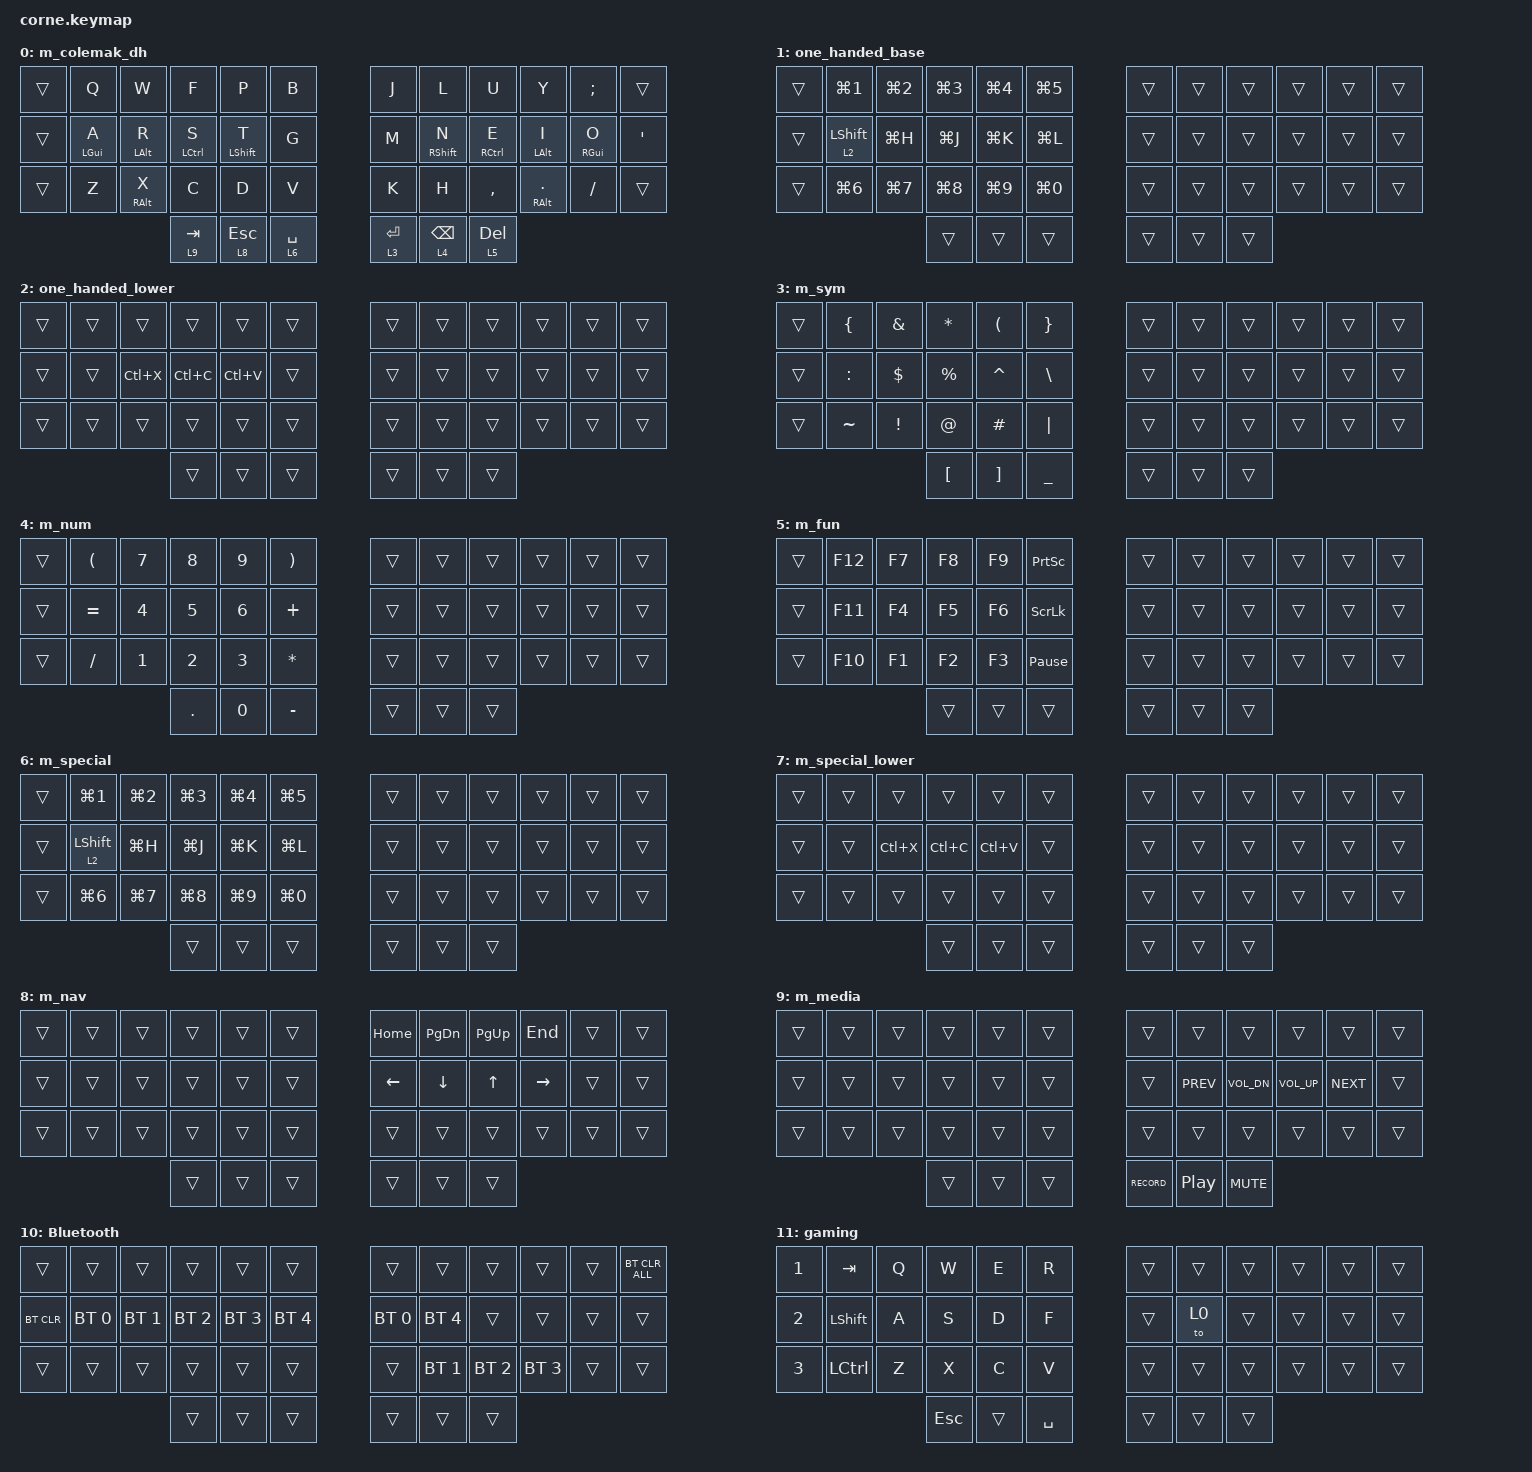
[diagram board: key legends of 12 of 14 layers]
/*
 * Copyright (c) 2020 The ZMK Contributors
 *
 * SPDX-License-Identifier: MIT
 */

#include <behaviors.dtsi>
#include <dt-bindings/zmk/bt.h>
#include <dt-bindings/zmk/keys.h>

/ {
    behaviors {
        lh_pht: left_hand_positional_hold_tap {
            compatible = "zmk,behavior-hold-tap";
            label = "LEFT_POSITIONAL_HOLD_TAP";
            bindings = <&kp>, <&kp>;

            #binding-cells = <2>;
            flavor = "tap-unless-interrupted";
            tapping-term-ms = <500>;
            hold-trigger-key-positions = <30 18 6 7 31 19 20 8 32 33 21 9 10 22 34 35 23 11>;
            quick-tap-ms = <200>;
            hold-trigger-on-release;
        };

        rh_pht: right_hand_positional_hold_tap {
            compatible = "zmk,behavior-hold-tap";
            label = "RIGHT_HAND_POSITIONAL_HOLD_TAP";
            bindings = <&kp>, <&kp>;

            #binding-cells = <2>;
            flavor = "tap-unless-interrupted";
            tapping-term-ms = <500>;
            quick-tap-ms = <200>;
            hold-trigger-key-positions = <0 1 2 3 4 5 12 13 14 15 16 17 24 25 26 27 28 29>;
            hold-trigger-on-release;
        };

        hl_ts: hold_layer_tap_sticky {
            compatible = "zmk,behavior-hold-tap";
            label = "HOLD_LAYER_TAP_STICKY";
            bindings = <&mo>, <&sk>;

            #binding-cells = <2>;
            tapping-term-ms = <100>;
        };

        lh_bpht: lh_bpht {
            compatible = "zmk,behavior-hold-tap";
            label = "LH_BPHT";
            bindings = <&kp>, <&kp>;

            #binding-cells = <2>;
            flavor = "balanced";
            tapping-term-ms = <500>;
            hold-trigger-key-positions = <30 18 6 7 31 19 20 8 32 33 21 9 10 22 34 35 23 11>;
            hold-trigger-on-release;
            quick-tap-ms = <200>;
        };

        rh_bpht: rh_bpht {
            compatible = "zmk,behavior-hold-tap";
            label = "RH_BPHT";
            bindings = <&kp>, <&kp>;

            #binding-cells = <2>;
            flavor = "balanced";
            tapping-term-ms = <500>;
            hold-trigger-on-release;
            hold-trigger-key-positions = <12 13 14 15 16 24 25 26 27 28 0 1 2 3 4 5 12 13 14 15 16 17 24 25 26 27 28 29>;
            quick-tap-ms = <200>;
        };

        balanced: balanced {
            compatible = "zmk,behavior-hold-tap";
            label = "BALANCED";
            bindings = <&kp>, <&kp>;

            #binding-cells = <2>;
            flavor = "balanced";
            tapping-term-ms = <1000>;
            quick-tap-ms = <200>;
        };

        lt_qt: lt_qt {
            compatible = "zmk,behavior-hold-tap";
            label = "LT_QT";
            bindings = <&mo>, <&kp>;

            #binding-cells = <2>;
            tapping-term-ms = <200>;
            quick-tap-ms = <200>;
            flavor = "tap-preferred";
        };
    };

    combos {
        compatible = "zmk,combos";

        one_handed {
            bindings = <&tog 1>;
            key-positions = <14 13 15 16>;
            layers = <13 1 2>;
        };
    };

    keymap {
        compatible = "zmk,keymap";

        m_colemak_dh {
            bindings = <
&trans  &kp Q                 &kp W                 &kp F              &kp P               &kp B             &kp J         &kp L               &kp U              &kp Y                 &kp SEMI          &trans
&trans  &balanced LEFT_GUI A  &balanced LEFT_ALT R  &balanced LCTRL S  &balanced LSHIFT T  &kp G             &kp M         &balanced RSHFT N   &balanced RCTRL E  &balanced LEFT_ALT I  &balanced RGUI O  &kp SQT
&trans  &kp Z                 &balanced RALT X      &kp C              &kp D               &kp V             &kp K         &kp H               &kp COMMA          &balanced RALT DOT    &kp FSLH          &trans
                                                    &lt_qt 9 TAB       &lt_qt 8 ESC        &lt_qt 6 SPACE    &lt_qt 3 RET  &lt_qt 4 BACKSPACE  &lt_qt 5 DEL
            >;
        };

        one_handed_base {
            bindings = <
&trans  &kp LG(N1)       &kp LG(N2)  &kp LG(N3)  &kp LG(N4)  &kp LG(N5)    &trans  &trans  &trans  &trans  &trans  &trans
&trans  &hl_ts 2 LSHIFT  &kp LG(H)   &kp LG(J)   &kp LG(K)   &kp LG(L)     &trans  &trans  &trans  &trans  &trans  &trans
&trans  &kp LG(N6)       &kp LG(N7)  &kp LG(N8)  &kp LG(N9)  &kp LG(N0)    &trans  &trans  &trans  &trans  &trans  &trans
                                     &trans      &trans      &trans        &trans  &trans  &trans
            >;
        };

        one_handed_lower {
            bindings = <
&trans  &trans  &trans     &trans     &trans     &trans    &trans  &trans  &trans  &trans  &trans  &trans
&trans  &trans  &kp LC(X)  &kp LC(C)  &kp LC(V)  &trans    &trans  &trans  &trans  &trans  &trans  &trans
&trans  &trans  &trans     &trans     &trans     &trans    &trans  &trans  &trans  &trans  &trans  &trans
                           &trans     &trans     &trans    &trans  &trans  &trans
            >;
        };

        m_sym {
            bindings = <
&trans  &kp LBRC   &kp AMPS         &kp ASTERISK      &kp LEFT_PARENTHESIS  &kp RIGHT_BRACE    &trans  &trans  &trans  &trans  &trans  &trans
&trans  &kp COLON  &kp DLLR         &kp PERCENT       &kp CARET             &kp BACKSLASH      &trans  &trans  &trans  &trans  &trans  &trans
&trans  &kp TILDE  &kp EXCLAMATION  &kp AT            &kp HASH              &kp PIPE           &trans  &trans  &trans  &trans  &trans  &trans
                                    &kp LEFT_BRACKET  &kp RIGHT_BRACKET     &kp UNDERSCORE     &trans  &trans  &trans
            >;
        };

        m_num {
            bindings = <
&trans  &kp LEFT_PARENTHESIS  &kp N7  &kp N8   &kp N9  &kp RIGHT_PARENTHESIS    &trans  &trans  &trans  &trans  &trans  &trans
&trans  &kp EQUAL             &kp N4  &kp N5   &kp N6  &kp PLUS                 &trans  &trans  &trans  &trans  &trans  &trans
&trans  &kp SLASH             &kp N1  &kp N2   &kp N3  &kp STAR                 &trans  &trans  &trans  &trans  &trans  &trans
                                      &kp DOT  &kp N0  &kp MINUS                &trans  &trans  &trans
            >;
        };

        m_fun {
            bindings = <
&trans  &kp F12  &kp F7  &kp F8  &kp F9  &kp PRINTSCREEN    &trans  &trans  &trans  &trans  &trans  &trans
&trans  &kp F11  &kp F4  &kp F5  &kp F6  &kp SCROLLLOCK     &trans  &trans  &trans  &trans  &trans  &trans
&trans  &kp F10  &kp F1  &kp F2  &kp F3  &kp PAUSE_BREAK    &trans  &trans  &trans  &trans  &trans  &trans
                         &trans  &trans  &trans             &trans  &trans  &trans
            >;
        };

        m_special {
            bindings = <
&trans  &kp LG(N1)       &kp LG(N2)  &kp LG(N3)  &kp LG(N4)  &kp LG(N5)    &trans  &trans  &trans  &trans  &trans  &trans
&trans  &hl_ts 2 LSHIFT  &kp LG(H)   &kp LG(J)   &kp LG(K)   &kp LG(L)     &trans  &trans  &trans  &trans  &trans  &trans
&trans  &kp LG(N6)       &kp LG(N7)  &kp LG(N8)  &kp LG(N9)  &kp LG(N0)    &trans  &trans  &trans  &trans  &trans  &trans
                                     &trans      &trans      &trans        &trans  &trans  &trans
            >;
        };

        m_special_lower {
            bindings = <
&trans  &trans  &trans     &trans     &trans     &trans    &trans  &trans  &trans  &trans  &trans  &trans
&trans  &trans  &kp LC(X)  &kp LC(C)  &kp LC(V)  &trans    &trans  &trans  &trans  &trans  &trans  &trans
&trans  &trans  &trans     &trans     &trans     &trans    &trans  &trans  &trans  &trans  &trans  &trans
                           &trans     &trans     &trans    &trans  &trans  &trans
            >;
        };

        m_nav {
            bindings = <
&trans  &trans  &trans  &trans  &trans  &trans    &kp HOME  &kp PG_DN  &kp PG_UP  &kp END    &trans  &trans
&trans  &trans  &trans  &trans  &trans  &trans    &kp LEFT  &kp DOWN   &kp UP     &kp RIGHT  &trans  &trans
&trans  &trans  &trans  &trans  &trans  &trans    &trans    &trans     &trans     &trans     &trans  &trans
                        &trans  &trans  &trans    &trans    &trans     &trans
            >;
        };

        m_media {
            bindings = <
&trans  &trans  &trans  &trans  &trans  &trans    &trans        &trans            &trans        &trans        &trans      &trans
&trans  &trans  &trans  &trans  &trans  &trans    &trans        &kp C_PREV        &kp C_VOL_DN  &kp C_VOL_UP  &kp C_NEXT  &trans
&trans  &trans  &trans  &trans  &trans  &trans    &trans        &trans            &trans        &trans        &trans      &trans
                        &trans  &trans  &trans    &kp C_RECORD  &kp C_PLAY_PAUSE  &kp C_MUTE
            >;
        };

        Bluetooth {
            bindings = <
&trans      &trans        &trans        &trans        &trans        &trans          &trans        &trans        &trans        &trans        &trans  &bt BT_CLR_ALL
&bt BT_CLR  &bt BT_SEL 0  &bt BT_SEL 1  &bt BT_SEL 2  &bt BT_SEL 3  &bt BT_SEL 4    &bt BT_SEL 0  &bt BT_SEL 4  &trans        &trans        &trans  &trans
&trans      &trans        &trans        &trans        &trans        &trans          &trans        &bt BT_SEL 1  &bt BT_SEL 2  &bt BT_SEL 3  &trans  &trans
                                        &trans        &trans        &trans          &trans        &trans        &trans
            >;
        };

        gaming {
            bindings = <
&kp N1  &kp TAB     &kp Q  &kp W    &kp E   &kp R        &trans  &trans  &trans  &trans  &trans  &trans
&kp N2  &kp LSHIFT  &kp A  &kp S    &kp D   &kp F        &trans  &to 0   &trans  &trans  &trans  &trans
&kp N3  &kp LCTRL   &kp Z  &kp X    &kp C   &kp V        &trans  &trans  &trans  &trans  &trans  &trans
                           &kp ESC  &trans  &kp SPACE    &trans  &trans  &trans
            >;
        };

        qwerty {
            bindings = <
&trans  &kp Q           &kp W           &kp E            &kp R             &kp T          &kp Y        &kp U                  &kp I            &kp O               &kp P                   &trans
&trans  &lh_pht LGUI A  &lh_pht LALT S  &lh_pht LCTRL D  &lh_pht LSHIFT F  &kp G          &kp H        &rh_pht RIGHT_SHIFT J  &rh_pht RCTRL K  &rh_pht LEFT_ALT L  &rh_pht RGUI SEMICOLON  &kp APOSTROPHE
&trans  &kp Z           &kp X           &kp C            &kp V             &kp B          &kp N        &kp M                  &kp COMMA        &kp DOT             &kp SLASH               &trans
                                        &kp TAB          &lt 0 ESC         &lt 0 SPACE    &lt 0 ENTER  &kp BACKSPACE          &kp DEL
            >;
        };

        layers {
            bindings = <
&trans  &to 13  &trans  &trans  &trans  &trans    &trans  &trans  &trans  &trans  &trans  &trans
&trans  &trans  &trans  &trans  &trans  &to 12    &trans  &trans  &trans  &trans  &trans  &trans
&trans  &trans  &trans  &to 0   &trans  &to 10    &trans  &trans  &trans  &trans  &trans  &trans
                        &trans  &trans  &trans    &trans  &trans  &trans
            >;
        };
    };

    conditional_layers {
        compatible = "zmk,conditional-layers";

        layer_nav {
            if-layers = <3 6>;
            then-layer = <13>;
        };
    };
};
